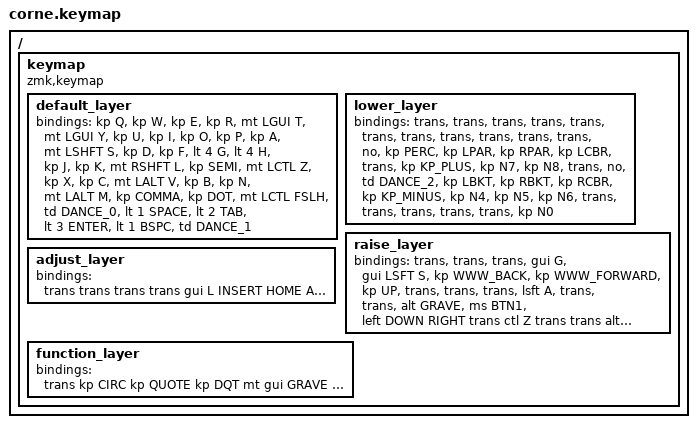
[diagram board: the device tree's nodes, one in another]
/*
 * Copyright (c) 2020 The ZMK Contributors
 *
 * SPDX-License-Identifier: MIT
 */

#include <behaviors.dtsi>
#include <dt-bindings/zmk/keys.h>
#include <dt-bindings/zmk/bt.h>

/ {
        keymap {
                compatible = "zmk,keymap";

                default_layer {
                        bindings = <
   &kp Q        &kp W        &kp E        &kp R        &mt LGUI T     &mt LGUI Y   &kp U         &kp I         &kp O         &kp P
   &kp A        &mt LSHFT S  &kp D        &kp F        &lt 4 G        &lt 4 H      &kp J         &kp K         &mt RSHFT L   &kp SEMI
   &mt LCTL Z   &kp X        &kp C        &mt LALT V   &kp B          &kp N        &mt LALT M    &kp COMMA     &kp DOT       &mt LCTL FSLH
                  &td DANCE_0  &lt 1 SPACE   &lt 2 TAB     &lt 3 ENTER    &lt 1 BSPC  &td DANCE_1
                        >;
                };
                lower_layer {
                        bindings = <
   &trans       &trans       &trans       &trans       &trans         &trans       &trans        &trans        &trans        &trans
   &trans       &no          &kp PERC     &kp LPAR     &kp RPAR       &kp LCBR     &trans        &kp KP_PLUS   &kp N7        &kp N8
   &trans       &no          &td DANCE_2  &kp LBKT     &kp RBKT       &kp RCBR     &kp KP_MINUS  &kp N4        &kp N5        &kp N6
                  &trans       &trans       &trans       &trans         &trans       &kp N0
                        >;
                };
                raise_layer {
                        bindings = <
   &trans       &trans       &trans       &gui G       &gui LSFT S    &kp WWW_BACK  &kp WWW_FORWARD  &kp UP      &trans       &trans
   &trans       &lsft A      &trans       &trans       &alt GRAVE     &ms BTN1      &left           DOWN         RIGHT       trans
   ctl Z        trans        trans        alt V        alt 1          ms BTN2      PAGE_UP         trans        PGDN         trans
                  trans         trans         trans         trans           trans         trans
                        >;
                };
                adjust_layer {
                        bindings = <
   trans         trans         trans         trans           gui L     INSERT          HOME           AUDIO_VOL_UP  trans         trans
   trans         lsft A        trans         trans           trans     DELETE          END            AUDIO_VOL_DOWN trans         trans
   ctl Z         trans         trans         alt V           trans     trans           trans          AUDIO_MUTE     trans         trans
                  trans         trans         trans           trans           trans         trans
                        >;
                };
                function_layer {
                        bindings = <
   trans         kp CIRC       kp QUOTE      kp DQT           mt gui GRAVE  gui L    F1              F2             F3             F4
   trans         td DANCE_4    kp AT         kp HASH          trans        trans    F5              F6             F7             F8
   ctl Z         trans         kp PIPE       td DANCE_5       kp BSLS       trans    F9              F10            F11            F12
                  trans         trans         trans           trans           trans         trans
                        >;
                };
        };
};
